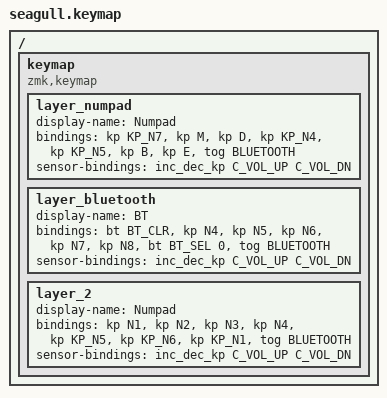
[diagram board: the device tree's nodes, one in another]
#include <behaviors.dtsi>
#include <dt-bindings/zmk/bt.h>
#include <dt-bindings/zmk/keys.h>

#define NUMPAD 0
#define BLUETOOTH 1

/ {
    keymap {
        compatible = "zmk,keymap";

        layer_numpad {
            display-name = "Numpad";

            // +---------------------------+                      
            // |   7  |   8  |   9  |   *  |                      
            // +------+------+------+------+
            // |   4  |   5  |   6  |   /  |                      
            // +------+------+------+------+-------+     
            // |   1  |   2  |   3  |   *  | L-BT  |                     
            // +------+------+------+------+-------+    
            // |   0  |   .  |  +   |   =  |                          
            // +------+------+------+------+  

            bindings = <
&kp KP_N7  &kp M  &kp D  &kp KP_N4  &kp KP_N5  &kp B  &kp E  &tog BLUETOOTH
            >;

            sensor-bindings = <&inc_dec_kp C_VOL_UP C_VOL_DN>;
        };

        layer_bluetooth {
            display-name = "BT";

            // +---------------------------+                      
            // |CLEAR |      |      |BTLDR |                      
            // +------+------+------+------+
            // |      |      |      |      |                      
            // +------+------+------+------+-------+     
            // | PF1  | PF2  |  PF3 |      | L-BT  |                      
            // +------+------+------+------+-------+    
            // |      |      |      |      |                          
            // +------+------+------+------+     

            bindings = <
&bt BT_CLR  &kp N4  &kp N5  &kp N6  &kp N7  &kp N8  &bt BT_SEL 0  &tog BLUETOOTH
            >;

            sensor-bindings = <&inc_dec_kp C_VOL_UP C_VOL_DN>;
        };

        layer_2 {
            display-name = "Numpad";
            bindings = <
&kp N1  &kp N2  &kp N3  &kp N4  &kp KP_N5  &kp KP_N6  &kp KP_N1  &tog BLUETOOTH
            >;

            sensor-bindings = <&inc_dec_kp C_VOL_UP C_VOL_DN>;
        };
    };
};
